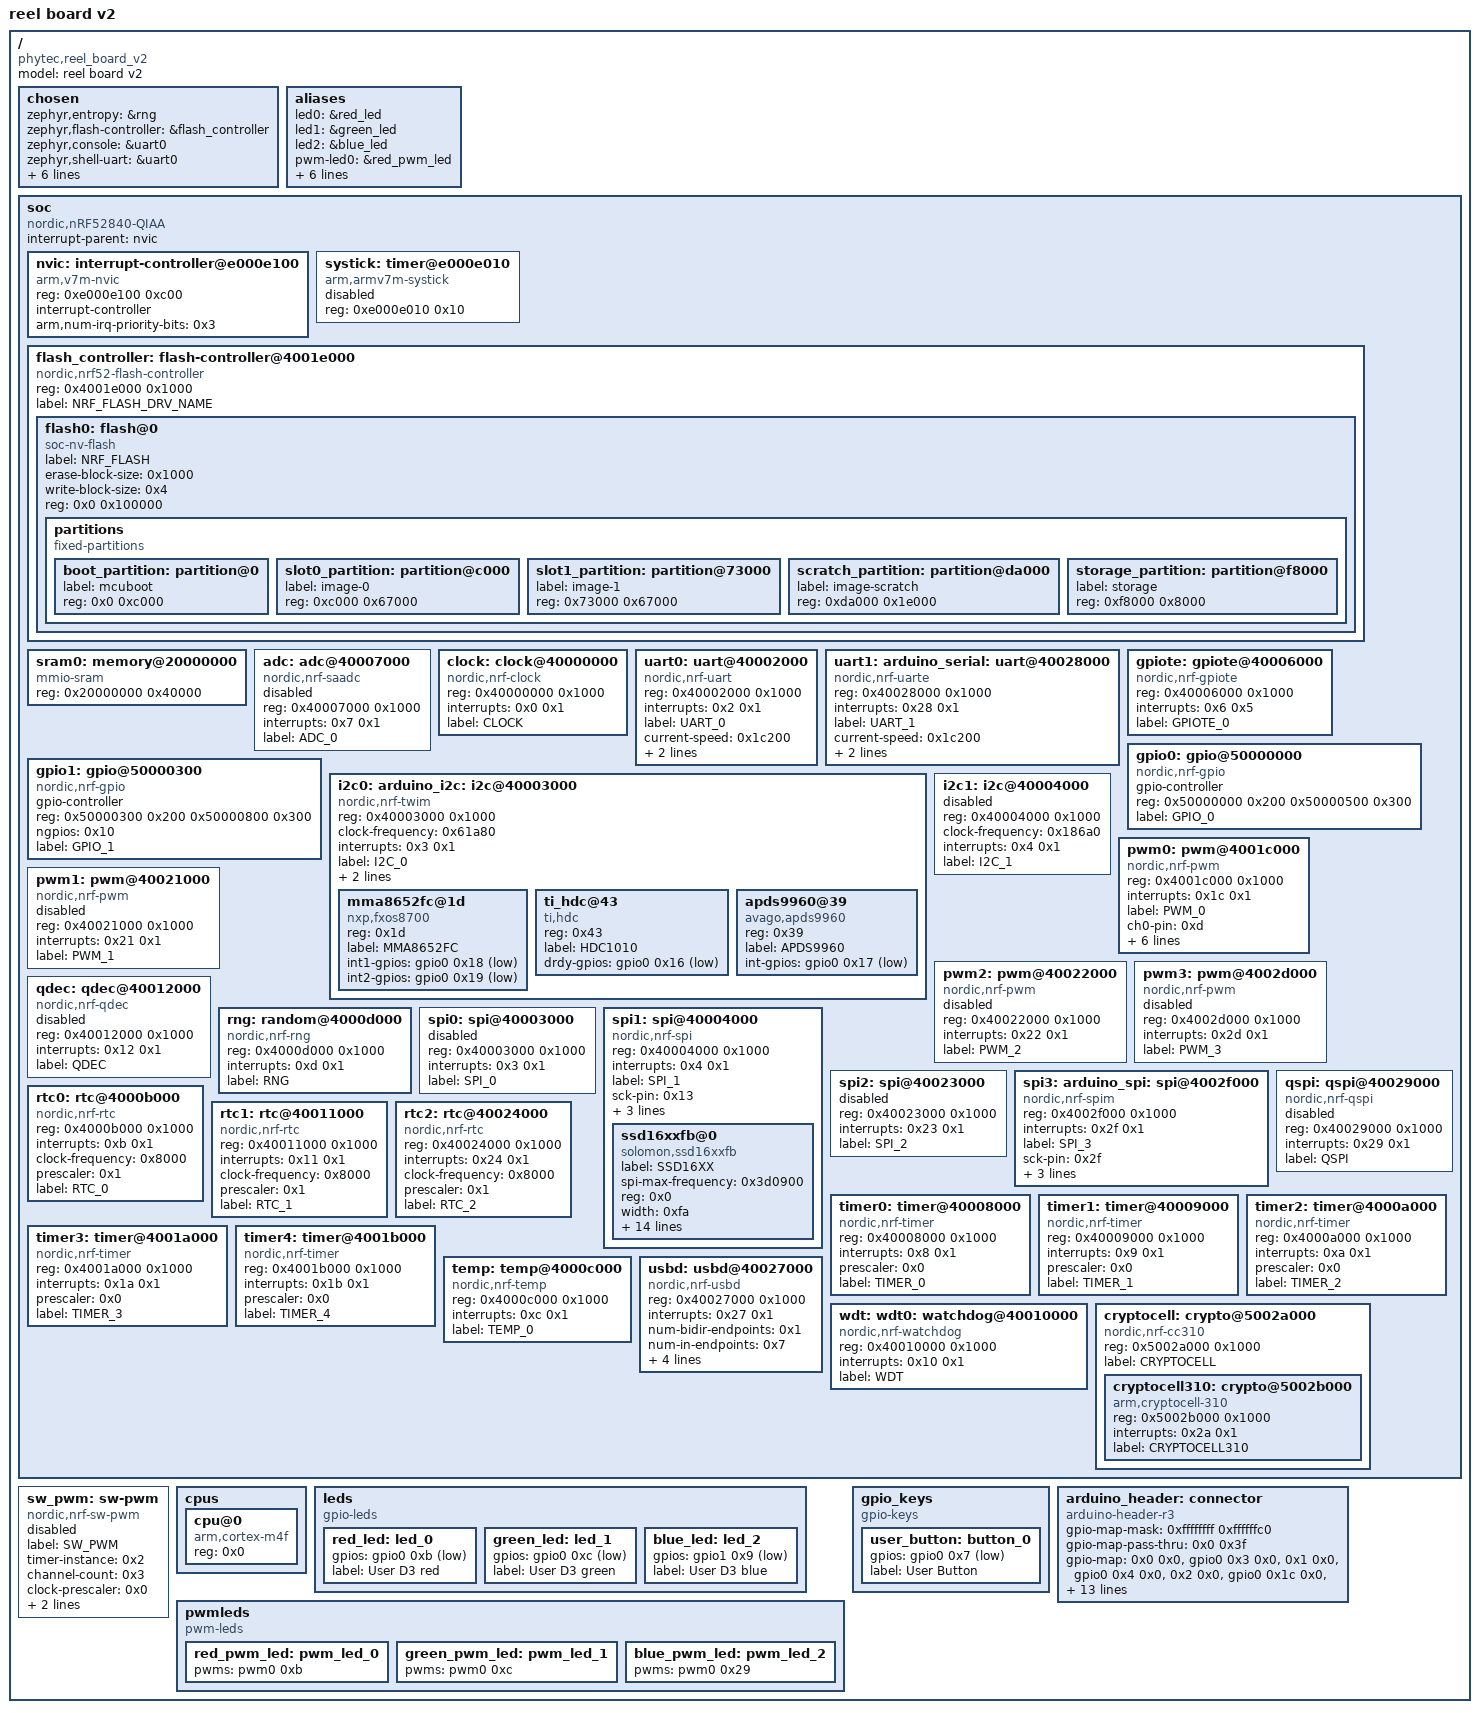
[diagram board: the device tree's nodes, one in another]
/dts-v1/;

/ {
	#address-cells = < 0x1 >;
	#size-cells = < 0x1 >;
	model = "reel board v2";
	compatible = "phytec,reel_board_v2";
	chosen {
		zephyr,entropy = &rng;
		zephyr,flash-controller = &flash_controller;
		zephyr,console = &uart0;
		zephyr,shell-uart = &uart0;
		zephyr,uart-mcumgr = &uart0;
		zephyr,bt-mon-uart = &uart0;
		zephyr,bt-c2h-uart = &uart0;
		zephyr,sram = &sram0;
		zephyr,flash = &flash0;
		zephyr,code-partition = &slot0_partition;
	};
	aliases {
		led0 = &red_led;
		led1 = &green_led;
		led2 = &blue_led;
		pwm-led0 = &red_pwm_led;
		pwm-led1 = &green_pwm_led;
		pwm-led2 = &blue_pwm_led;
		red-pwm-led = &red_pwm_led;
		green-pwm-led = &green_pwm_led;
		blue-pwm-led = &blue_pwm_led;
		sw0 = &user_button;
	};
	soc {
		#address-cells = < 0x1 >;
		#size-cells = < 0x1 >;
		compatible = "nordic,nRF52840-QIAA", "nordic,nRF52840", "nordic,nRF52", "simple-bus";
		interrupt-parent = < &nvic >;
		ranges;
		nvic: interrupt-controller@e000e100 {
			compatible = "arm,v7m-nvic";
			reg = < 0xe000e100 0xc00 >;
			interrupt-controller;
			#interrupt-cells = < 0x2 >;
			arm,num-irq-priority-bits = < 0x3 >;
			phandle = < 0x1 >;
		};
		systick: timer@e000e010 {
			compatible = "arm,armv7m-systick";
			reg = < 0xe000e010 0x10 >;
			status = "disabled";
		};
		flash_controller: flash-controller@4001e000 {
			compatible = "nordic,nrf52-flash-controller";
			reg = < 0x4001e000 0x1000 >;
			#address-cells = < 0x1 >;
			#size-cells = < 0x1 >;
			label = "NRF_FLASH_DRV_NAME";
			flash0: flash@0 {
				compatible = "soc-nv-flash";
				label = "NRF_FLASH";
				erase-block-size = < 0x1000 >;
				write-block-size = < 0x4 >;
				reg = < 0x0 0x100000 >;
				partitions {
					compatible = "fixed-partitions";
					#address-cells = < 0x1 >;
					#size-cells = < 0x1 >;
					boot_partition: partition@0 {
						label = "mcuboot";
						reg = < 0x0 0xc000 >;
					};
					slot0_partition: partition@c000 {
						label = "image-0";
						reg = < 0xc000 0x67000 >;
					};
					slot1_partition: partition@73000 {
						label = "image-1";
						reg = < 0x73000 0x67000 >;
					};
					scratch_partition: partition@da000 {
						label = "image-scratch";
						reg = < 0xda000 0x1e000 >;
					};
					storage_partition: partition@f8000 {
						label = "storage";
						reg = < 0xf8000 0x8000 >;
					};
				};
			};
		};
		sram0: memory@20000000 {
			compatible = "mmio-sram";
			reg = < 0x20000000 0x40000 >;
		};
		adc: adc@40007000 {
			compatible = "nordic,nrf-saadc";
			reg = < 0x40007000 0x1000 >;
			interrupts = < 0x7 0x1 >;
			status = "disabled";
			label = "ADC_0";
			#io-channel-cells = < 0x1 >;
		};
		clock: clock@40000000 {
			compatible = "nordic,nrf-clock";
			reg = < 0x40000000 0x1000 >;
			interrupts = < 0x0 0x1 >;
			status = "okay";
			label = "CLOCK";
		};
		uart0: uart@40002000 {
			reg = < 0x40002000 0x1000 >;
			interrupts = < 0x2 0x1 >;
			status = "okay";
			label = "UART_0";
			compatible = "nordic,nrf-uart";
			current-speed = < 0x1c200 >;
			tx-pin = < 0x6 >;
			rx-pin = < 0x8 >;
		};
		uart1: arduino_serial: uart@40028000 {
			compatible = "nordic,nrf-uarte";
			reg = < 0x40028000 0x1000 >;
			interrupts = < 0x28 0x1 >;
			status = "okay";
			label = "UART_1";
			current-speed = < 0x1c200 >;
			rx-pin = < 0x21 >;
			tx-pin = < 0x22 >;
		};
		gpiote: gpiote@40006000 {
			compatible = "nordic,nrf-gpiote";
			reg = < 0x40006000 0x1000 >;
			interrupts = < 0x6 0x5 >;
			status = "okay";
			label = "GPIOTE_0";
		};
		gpio0: gpio@50000000 {
			compatible = "nordic,nrf-gpio";
			gpio-controller;
			reg = < 0x50000000 0x200 0x50000500 0x300 >;
			#gpio-cells = < 0x2 >;
			label = "GPIO_0";
			status = "okay";
			phandle = < 0x2 >;
		};
		gpio1: gpio@50000300 {
			compatible = "nordic,nrf-gpio";
			gpio-controller;
			reg = < 0x50000300 0x200 0x50000800 0x300 >;
			#gpio-cells = < 0x2 >;
			ngpios = < 0x10 >;
			label = "GPIO_1";
			status = "okay";
			phandle = < 0x4 >;
		};
		i2c0: arduino_i2c: i2c@40003000 {
			#address-cells = < 0x1 >;
			#size-cells = < 0x0 >;
			reg = < 0x40003000 0x1000 >;
			clock-frequency = < 0x61a80 >;
			interrupts = < 0x3 0x1 >;
			status = "okay";
			label = "I2C_0";
			compatible = "nordic,nrf-twim";
			sda-pin = < 0x1a >;
			scl-pin = < 0x1b >;
			mma8652fc@1d {
				compatible = "nxp,fxos8700", "nxp,mma8652fc";
				reg = < 0x1d >;
				label = "MMA8652FC";
				int1-gpios = < &gpio0 0x18 0x1 >;
				int2-gpios = < &gpio0 0x19 0x1 >;
			};
			ti_hdc@43 {
				compatible = "ti,hdc", "ti,hdc1010";
				reg = < 0x43 >;
				label = "HDC1010";
				drdy-gpios = < &gpio0 0x16 0x11 >;
			};
			apds9960@39 {
				compatible = "avago,apds9960";
				reg = < 0x39 >;
				label = "APDS9960";
				int-gpios = < &gpio0 0x17 0x11 >;
			};
		};
		i2c1: i2c@40004000 {
			#address-cells = < 0x1 >;
			#size-cells = < 0x0 >;
			reg = < 0x40004000 0x1000 >;
			clock-frequency = < 0x186a0 >;
			interrupts = < 0x4 0x1 >;
			status = "disabled";
			label = "I2C_1";
		};
		pwm0: pwm@4001c000 {
			compatible = "nordic,nrf-pwm";
			reg = < 0x4001c000 0x1000 >;
			interrupts = < 0x1c 0x1 >;
			status = "okay";
			label = "PWM_0";
			#pwm-cells = < 0x1 >;
			ch0-pin = < 0xd >;
			ch1-pin = < 0xb >;
			ch1-inverted;
			ch2-pin = < 0xc >;
			ch2-inverted;
			ch3-pin = < 0x29 >;
			ch3-inverted;
			phandle = < 0x5 >;
		};
		pwm1: pwm@40021000 {
			compatible = "nordic,nrf-pwm";
			reg = < 0x40021000 0x1000 >;
			interrupts = < 0x21 0x1 >;
			status = "disabled";
			label = "PWM_1";
			#pwm-cells = < 0x1 >;
		};
		pwm2: pwm@40022000 {
			compatible = "nordic,nrf-pwm";
			reg = < 0x40022000 0x1000 >;
			interrupts = < 0x22 0x1 >;
			status = "disabled";
			label = "PWM_2";
			#pwm-cells = < 0x1 >;
		};
		pwm3: pwm@4002d000 {
			compatible = "nordic,nrf-pwm";
			reg = < 0x4002d000 0x1000 >;
			interrupts = < 0x2d 0x1 >;
			status = "disabled";
			label = "PWM_3";
			#pwm-cells = < 0x1 >;
		};
		qdec: qdec@40012000 {
			compatible = "nordic,nrf-qdec";
			reg = < 0x40012000 0x1000 >;
			interrupts = < 0x12 0x1 >;
			status = "disabled";
			label = "QDEC";
		};
		rng: random@4000d000 {
			compatible = "nordic,nrf-rng";
			reg = < 0x4000d000 0x1000 >;
			interrupts = < 0xd 0x1 >;
			status = "okay";
			label = "RNG";
		};
		spi0: spi@40003000 {
			#address-cells = < 0x1 >;
			#size-cells = < 0x0 >;
			reg = < 0x40003000 0x1000 >;
			interrupts = < 0x3 0x1 >;
			status = "disabled";
			label = "SPI_0";
		};
		spi1: spi@40004000 {
			#address-cells = < 0x1 >;
			#size-cells = < 0x0 >;
			reg = < 0x40004000 0x1000 >;
			interrupts = < 0x4 0x1 >;
			status = "okay";
			label = "SPI_1";
			compatible = "nordic,nrf-spi";
			sck-pin = < 0x13 >;
			mosi-pin = < 0x14 >;
			miso-pin = < 0x15 >;
			cs-gpios = < &gpio0 0x11 0x1 >;
			ssd16xxfb@0 {
				compatible = "solomon,ssd16xxfb", "gooddisplay,gdeh0213b72";
				label = "SSD16XX";
				spi-max-frequency = < 0x3d0900 >;
				reg = < 0x0 >;
				width = < 0xfa >;
				height = < 0x7a >;
				pp-width-bits = < 0x8 >;
				pp-height-bits = < 0x10 >;
				reset-gpios = < &gpio0 0xf 0x1 >;
				dc-gpios = < &gpio0 0x10 0x1 >;
				busy-gpios = < &gpio0 0xe 0x0 >;
				gdv = [ 15 ];
				sdv = [ 41 A8 32 ];
				vcom = < 0x26 >;
				border-waveform = < 0x3 >;
				lut-initial = [ 80 60 40 00 00 00 00 10 60 20 00 00 00 00 80 60 40 00 00 00 00 10 60 20 00 00 00 00 00 00 00 00 00 00 00 03 03 00 00 02 09 09 00 00 02 03 03 00 00 02 00 00 00 00 00 00 00 00 00 00 00 00 00 00 00 00 00 00 00 00 ];
				lut-default = [ 00 00 00 00 00 00 00 80 00 00 00 00 00 00 40 00 00 00 00 00 00 80 00 00 00 00 00 00 00 00 00 00 00 00 00 0A 00 00 00 04 00 00 00 00 00 00 00 00 00 00 00 00 00 00 00 00 00 00 00 00 00 00 00 00 00 00 00 00 00 00 ];
			};
		};
		spi2: spi@40023000 {
			#address-cells = < 0x1 >;
			#size-cells = < 0x0 >;
			reg = < 0x40023000 0x1000 >;
			interrupts = < 0x23 0x1 >;
			status = "disabled";
			label = "SPI_2";
		};
		spi3: arduino_spi: spi@4002f000 {
			compatible = "nordic,nrf-spim";
			#address-cells = < 0x1 >;
			#size-cells = < 0x0 >;
			reg = < 0x4002f000 0x1000 >;
			interrupts = < 0x2f 0x1 >;
			status = "okay";
			label = "SPI_3";
			sck-pin = < 0x2f >;
			miso-pin = < 0x2e >;
			mosi-pin = < 0x2d >;
			cs-gpios = < &arduino_header 0x10 0x1 >;
		};
		qspi: qspi@40029000 {
			compatible = "nordic,nrf-qspi";
			#address-cells = < 0x1 >;
			#size-cells = < 0x0 >;
			reg = < 0x40029000 0x1000 >;
			interrupts = < 0x29 0x1 >;
			status = "disabled";
			label = "QSPI";
		};
		rtc0: rtc@4000b000 {
			compatible = "nordic,nrf-rtc";
			reg = < 0x4000b000 0x1000 >;
			interrupts = < 0xb 0x1 >;
			status = "okay";
			clock-frequency = < 0x8000 >;
			prescaler = < 0x1 >;
			label = "RTC_0";
		};
		rtc1: rtc@40011000 {
			compatible = "nordic,nrf-rtc";
			reg = < 0x40011000 0x1000 >;
			interrupts = < 0x11 0x1 >;
			status = "okay";
			clock-frequency = < 0x8000 >;
			prescaler = < 0x1 >;
			label = "RTC_1";
		};
		rtc2: rtc@40024000 {
			compatible = "nordic,nrf-rtc";
			reg = < 0x40024000 0x1000 >;
			interrupts = < 0x24 0x1 >;
			status = "okay";
			clock-frequency = < 0x8000 >;
			prescaler = < 0x1 >;
			label = "RTC_2";
		};
		timer0: timer@40008000 {
			compatible = "nordic,nrf-timer";
			status = "okay";
			reg = < 0x40008000 0x1000 >;
			interrupts = < 0x8 0x1 >;
			prescaler = < 0x0 >;
			label = "TIMER_0";
		};
		timer1: timer@40009000 {
			compatible = "nordic,nrf-timer";
			status = "okay";
			reg = < 0x40009000 0x1000 >;
			interrupts = < 0x9 0x1 >;
			prescaler = < 0x0 >;
			label = "TIMER_1";
		};
		timer2: timer@4000a000 {
			compatible = "nordic,nrf-timer";
			status = "okay";
			reg = < 0x4000a000 0x1000 >;
			interrupts = < 0xa 0x1 >;
			prescaler = < 0x0 >;
			label = "TIMER_2";
		};
		timer3: timer@4001a000 {
			compatible = "nordic,nrf-timer";
			status = "okay";
			reg = < 0x4001a000 0x1000 >;
			interrupts = < 0x1a 0x1 >;
			prescaler = < 0x0 >;
			label = "TIMER_3";
		};
		timer4: timer@4001b000 {
			compatible = "nordic,nrf-timer";
			status = "okay";
			reg = < 0x4001b000 0x1000 >;
			interrupts = < 0x1b 0x1 >;
			prescaler = < 0x0 >;
			label = "TIMER_4";
		};
		temp: temp@4000c000 {
			compatible = "nordic,nrf-temp";
			reg = < 0x4000c000 0x1000 >;
			interrupts = < 0xc 0x1 >;
			status = "okay";
			label = "TEMP_0";
		};
		usbd: usbd@40027000 {
			compatible = "nordic,nrf-usbd";
			reg = < 0x40027000 0x1000 >;
			interrupts = < 0x27 0x1 >;
			num-bidir-endpoints = < 0x1 >;
			num-in-endpoints = < 0x7 >;
			num-out-endpoints = < 0x7 >;
			num-isoin-endpoints = < 0x1 >;
			num-isoout-endpoints = < 0x1 >;
			status = "okay";
			label = "USBD";
		};
		wdt: wdt0: watchdog@40010000 {
			compatible = "nordic,nrf-watchdog";
			reg = < 0x40010000 0x1000 >;
			interrupts = < 0x10 0x1 >;
			status = "okay";
			label = "WDT";
		};
		cryptocell: crypto@5002a000 {
			compatible = "nordic,nrf-cc310";
			reg = < 0x5002a000 0x1000 >;
			label = "CRYPTOCELL";
			status = "okay";
			#address-cells = < 0x1 >;
			#size-cells = < 0x1 >;
			cryptocell310: crypto@5002b000 {
				compatible = "arm,cryptocell-310";
				reg = < 0x5002b000 0x1000 >;
				interrupts = < 0x2a 0x1 >;
				label = "CRYPTOCELL310";
			};
		};
	};
	sw_pwm: sw-pwm {
		compatible = "nordic,nrf-sw-pwm";
		status = "disabled";
		label = "SW_PWM";
		timer-instance = < 0x2 >;
		channel-count = < 0x3 >;
		clock-prescaler = < 0x0 >;
		ppi-base = < 0xe >;
		gpiote-base = < 0x0 >;
		#pwm-cells = < 0x1 >;
	};
	cpus {
		#address-cells = < 0x1 >;
		#size-cells = < 0x0 >;
		cpu@0 {
			device_type = "cpu";
			compatible = "arm,cortex-m4f";
			reg = < 0x0 >;
		};
	};
	leds {
		compatible = "gpio-leds";
		red_led: led_0 {
			gpios = < &gpio0 0xb 0x1 >;
			label = "User D3 red";
		};
		green_led: led_1 {
			gpios = < &gpio0 0xc 0x1 >;
			label = "User D3 green";
		};
		blue_led: led_2 {
			gpios = < &gpio1 0x9 0x1 >;
			label = "User D3 blue";
		};
	};
	pwmleds {
		compatible = "pwm-leds";
		red_pwm_led: pwm_led_0 {
			pwms = < &pwm0 0xb >;
		};
		green_pwm_led: pwm_led_1 {
			pwms = < &pwm0 0xc >;
		};
		blue_pwm_led: pwm_led_2 {
			pwms = < &pwm0 0x29 >;
		};
	};
	gpio_keys {
		compatible = "gpio-keys";
		user_button: button_0 {
			gpios = < &gpio0 0x7 0x11 >;
			label = "User Button";
		};
	};
	arduino_header: connector {
		compatible = "arduino-header-r3";
		#gpio-cells = < 0x2 >;
		gpio-map-mask = < 0xffffffff 0xffffffc0 >;
		gpio-map-pass-thru = < 0x0 0x3f >;
		gpio-map = < 0x0 0x0 &gpio0 0x3 0x0 >, < 0x1 0x0 &gpio0 0x4 0x0 >, < 0x2 0x0 &gpio0 0x1c 0x0 >, < 0x3 0x0 &gpio0 0x1d 0x0 >, < 0x4 0x0 &gpio0 0x1e 0x0 >, < 0x5 0x0 &gpio0 0x1f 0x0 >, < 0x6 0x0 &gpio1 0x1 0x0 >, < 0x7 0x0 &gpio1 0x2 0x0 >, < 0x8 0x0 &gpio1 0x3 0x0 >, < 0x9 0x0 &gpio1 0x4 0x0 >, < 0xa 0x0 &gpio1 0x5 0x0 >, < 0xb 0x0 &gpio1 0x6 0x0 >, < 0xc 0x0 &gpio1 0x7 0x0 >, < 0xd 0x0 &gpio1 0x8 0x0 >, < 0xe 0x0 &gpio1 0xa 0x0 >, < 0xf 0x0 &gpio1 0xb 0x0 >, < 0x10 0x0 &gpio1 0xc 0x0 >, < 0x11 0x0 &gpio1 0xd 0x0 >, < 0x12 0x0 &gpio1 0xe 0x0 >, < 0x13 0x0 &gpio1 0xf 0x0 >, < 0x14 0x0 &gpio0 0x1a 0x0 >, < 0x15 0x0 &gpio0 0x1b 0x0 >;
		phandle = < 0x3 >;
	};
};
